AUTOSAR XML (schema 4-0-3)
package /ComponentTypes
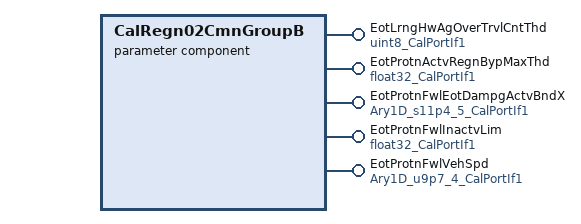
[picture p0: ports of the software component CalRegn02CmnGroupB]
  parameter sw component type CalRegn02CmnGroupB
    5 x provide port:
      EotLrngHwAgOverTrvlCntThd: parameter-provide-com-spec{init-value=5, parameter=Val}, provided-interface=uint8_CalPortIf1
      EotProtnActvRegnBypMaxThd: parameter-provide-com-spec{init-value=0.5, parameter=Val}, provided-interface=float32_CalPortIf1
      EotProtnFwlEotDampgActvBndX: parameter-provide-com-spec{init-value=[-11200, -80, 160, 800, 11200], parameter=Ary1D}, provided-interface=Ary1D_s11p4_5_CalPortIf1
      EotProtnFwlInactvLim: parameter-provide-com-spec{init-value=0.1, parameter=Val}, provided-interface=float32_CalPortIf1
      EotProtnFwlVehSpd: parameter-provide-com-spec{init-value=[0, 2560, 5120, 7680], parameter=Ary1D}, provided-interface=Ary1D_u9p7_4_CalPortIf1
